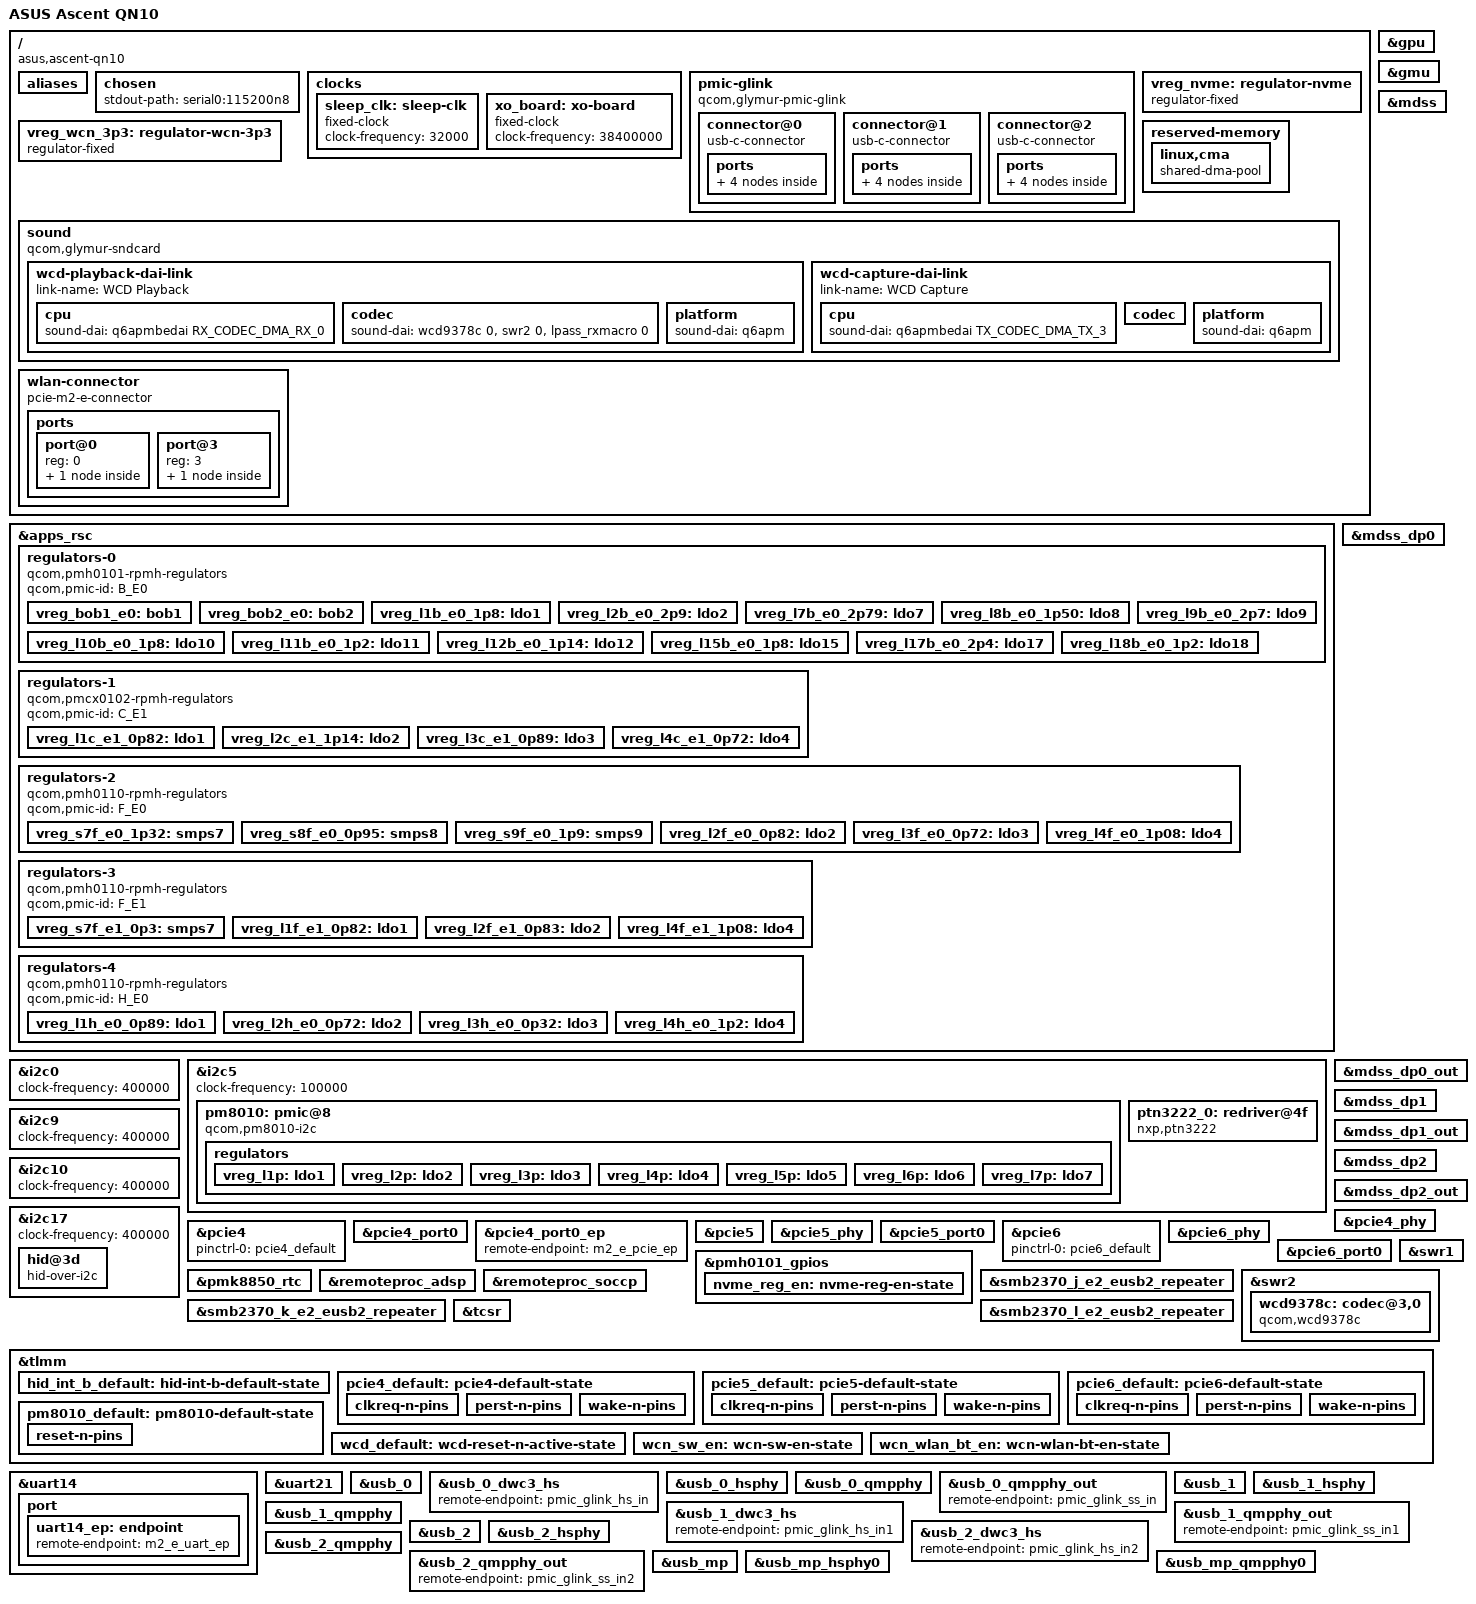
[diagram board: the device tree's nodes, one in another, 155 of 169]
// SPDX-License-Identifier: BSD-3-Clause
/*
 * Copyright (c) Qualcomm Technologies, Inc. and/or its subsidiaries.
 */
/dts-v1/;

#include "glymur.dtsi"

#include "pmcx0102.dtsi"        /* SPMI0: SID-2/3 SPMI1: SID-2/3 */
#include "pmh0101.dtsi"         /* SPMI0: SID-1                  */
#include "pmh0110-glymur.dtsi"  /* SPMI0: SID-5/7 SPMI1: SID-5   */
#include "pmh0104-glymur.dtsi"  /* SPMI0: SID-8/9 SPMI1: SID-11  */
#include "pmk8850.dtsi"         /* SPMI0: SID-0                  */
#include "smb2370.dtsi"         /* SPMI2: SID-9/10/11            */

/ {
	model = "ASUS Ascent QN10";
	compatible = "asus,ascent-qn10", "qcom,glymur";
	chassis-type = "desktop";

	aliases {
		i2c0 = &i2c0;
		i2c5 = &i2c5;
		i2c9 = &i2c9;
		i2c10 = &i2c10;
		i2c17 = &i2c17;

		serial0 = &uart21;
		serial1 = &uart14;
	};

	chosen {
		stdout-path = "serial0:115200n8";
	};

	clocks {
		sleep_clk: sleep-clk {
			compatible = "fixed-clock";
			clock-frequency = <32000>;
			#clock-cells = <0>;
		};

		xo_board: xo-board {
			compatible = "fixed-clock";
			clock-frequency = <38400000>;
			#clock-cells = <0>;
		};
	};

	/*
	 * Three Type-C ports and no battery. The mapping of the connectors to
	 * the USB controllers is not known. The rear HDMI port is not described.
	 */
	pmic-glink {
		compatible = "qcom,glymur-pmic-glink",
			     "qcom,pmic-glink";
		#address-cells = <1>;
		#size-cells = <0>;

		/* Assumed front left */
		connector@0 {
			compatible = "usb-c-connector";
			reg = <0>;
			power-role = "dual";
			data-role = "dual";

			ports {
				#address-cells = <1>;
				#size-cells = <0>;

				port@0 {
					reg = <0>;

					pmic_glink_hs_in: endpoint {
						remote-endpoint = <&usb_0_dwc3_hs>;
					};
				};

				port@1 {
					reg = <1>;

					pmic_glink_ss_in: endpoint {
						remote-endpoint = <&usb_0_qmpphy_out>;
					};
				};
			};
		};

		/* Assumed front right */
		connector@1 {
			compatible = "usb-c-connector";
			reg = <1>;
			power-role = "dual";
			data-role = "dual";

			ports {
				#address-cells = <1>;
				#size-cells = <0>;

				port@0 {
					reg = <0>;

					pmic_glink_hs_in1: endpoint {
						remote-endpoint = <&usb_1_dwc3_hs>;
					};
				};

				port@1 {
					reg = <1>;

					pmic_glink_ss_in1: endpoint {
						remote-endpoint = <&usb_1_qmpphy_out>;
					};
				};
			};
		};

		/* Assumed rear */
		connector@2 {
			compatible = "usb-c-connector";
			reg = <2>;
			power-role = "dual";
			data-role = "dual";

			ports {
				#address-cells = <1>;
				#size-cells = <0>;

				port@0 {
					reg = <0>;

					pmic_glink_hs_in2: endpoint {
						remote-endpoint = <&usb_2_dwc3_hs>;
					};
				};

				port@1 {
					reg = <1>;

					pmic_glink_ss_in2: endpoint {
						remote-endpoint = <&usb_2_qmpphy_out>;
					};
				};
			};
		};
	};

	vreg_nvme: regulator-nvme {
		compatible = "regulator-fixed";

		regulator-name = "VREG_NVME_3P3";
		regulator-min-microvolt = <3300000>;
		regulator-max-microvolt = <3300000>;

		gpio = <&pmh0101_gpios 14 GPIO_ACTIVE_HIGH>;
		enable-active-high;

		pinctrl-0 = <&nvme_reg_en>;
		pinctrl-names = "default";

		regulator-boot-on;
	};

	vreg_wcn_3p3: regulator-wcn-3p3 {
		compatible = "regulator-fixed";

		regulator-name = "VREG_WCN_3P3";
		regulator-min-microvolt = <3300000>;
		regulator-max-microvolt = <3300000>;

		gpio = <&tlmm 94 GPIO_ACTIVE_HIGH>;
		enable-active-high;

		pinctrl-0 = <&wcn_sw_en>;
		pinctrl-names = "default";

		regulator-boot-on;
	};

	reserved-memory {
		linux,cma {
			compatible = "shared-dma-pool";
			size = <0x0 0x10000000>;
			reusable;
			linux,cma-default;
		};
	};

	/*
	 * Only the WCD9378 links are used. There are no WSA amplifiers or
	 * digital microphones.
	 */
	sound {
		compatible = "qcom,glymur-sndcard";
		model = "GLYMUR-ASUS-Ascent-QN10";

		audio-routing = "IT 41 Playback", "HPHL_OUT",
				"IT 41 Playback", "HPHR_OUT",
				/* Bridge the TX macro input to the WCD capture terminal */
				"TX SWR_INPUT1", "OT 36 Capture";

		/*
		 * swr2 is the bus master and swr1 its lane provider, so both DAI
		 * links reference &swr2 (cell 0 dout, cell 1 din).
		 */
		wcd-playback-dai-link {
			link-name = "WCD Playback";

			cpu {
				sound-dai = <&q6apmbedai RX_CODEC_DMA_RX_0>;
			};

			codec {
				sound-dai = <&wcd9378c 0>, <&swr2 0>, <&lpass_rxmacro 0>;
			};

			platform {
				sound-dai = <&q6apm>;
			};
		};

		wcd-capture-dai-link {
			link-name = "WCD Capture";

			cpu {
				sound-dai = <&q6apmbedai TX_CODEC_DMA_TX_3>;
			};

			codec {
				sound-dai = <&wcd9378c 18>, <&swr2 1>, <&lpass_txmacro 0>;
			};

			platform {
				sound-dai = <&q6apm>;
			};
		};
	};

	/*
	 * Generic M.2 E-key connector. The module is a Foxconn NCM820A
	 * (FastConnect C7700, PCI 17cb:1112), not the WCN7850 of the QCB and
	 * CRD. Bluetooth is a UART device on uart14.
	 */
	wlan-connector {
		compatible = "pcie-m2-e-connector";
		vpcie3v3-supply = <&vreg_wcn_3p3>;
		vpcie1v8-supply = <&vreg_l15b_e0_1p8>;

		w-disable1-gpios = <&tlmm 117 GPIO_ACTIVE_LOW>;
		w-disable2-gpios = <&tlmm 116 GPIO_ACTIVE_LOW>;

		pinctrl-0 = <&wcn_wlan_bt_en>;
		pinctrl-names = "default";

		ports {
			#address-cells = <1>;
			#size-cells = <0>;

			port@0 {
				reg = <0>;

				m2_e_pcie_ep: endpoint {
					remote-endpoint = <&pcie4_port0_ep>;
				};
			};

			port@3 {
				reg = <3>;

				m2_e_uart_ep: endpoint {
					remote-endpoint = <&uart14_ep>;
				};
			};
		};
	};
};

/*
 * RPMh regulator table of the CRD family (B_E0, C_E1, F_E0, F_E1, H_E0). The
 * rail plan is assumed to match the CRD.
 */
&apps_rsc {
	regulators-0 {
		compatible = "qcom,pmh0101-rpmh-regulators";
		qcom,pmic-id = "B_E0";

		vreg_bob1_e0: bob1 {
			regulator-name = "vreg_bob1_e0";
			regulator-min-microvolt = <2200000>;
			regulator-max-microvolt = <4224000>;
			regulator-initial-mode = <RPMH_REGULATOR_MODE_AUTO>;
		};

		vreg_bob2_e0: bob2 {
			regulator-name = "vreg_bob2_e0";
			regulator-min-microvolt = <2540000>;
			regulator-max-microvolt = <3600000>;
			regulator-initial-mode = <RPMH_REGULATOR_MODE_AUTO>;
		};

		vreg_l1b_e0_1p8: ldo1 {
			regulator-name = "vreg_l1b_e0_1p8";
			regulator-min-microvolt = <1800000>;
			regulator-max-microvolt = <1800000>;
			regulator-initial-mode = <RPMH_REGULATOR_MODE_HPM>;
		};

		vreg_l2b_e0_2p9: ldo2 {
			regulator-name = "vreg_l2b_e0_2p9";
			regulator-min-microvolt = <2904000>;
			regulator-max-microvolt = <2904000>;
			regulator-initial-mode = <RPMH_REGULATOR_MODE_HPM>;
		};

		vreg_l7b_e0_2p79: ldo7 {
			regulator-name = "vreg_l7b_e0_2p79";
			regulator-min-microvolt = <2790000>;
			regulator-max-microvolt = <2792000>;
			regulator-initial-mode = <RPMH_REGULATOR_MODE_HPM>;
		};

		vreg_l8b_e0_1p50: ldo8 {
			regulator-name = "vreg_l8b_e0_1p50";
			regulator-min-microvolt = <1504000>;
			regulator-max-microvolt = <1504000>;
			regulator-initial-mode = <RPMH_REGULATOR_MODE_HPM>;
		};

		vreg_l9b_e0_2p7: ldo9 {
			regulator-name = "vreg_l9b_e0_2p7";
			regulator-min-microvolt = <2704000>;
			regulator-max-microvolt = <2704000>;
			regulator-initial-mode = <RPMH_REGULATOR_MODE_HPM>;
		};

		vreg_l10b_e0_1p8: ldo10 {
			regulator-name = "vreg_l10b_e0_1p8";
			regulator-min-microvolt = <1800000>;
			regulator-max-microvolt = <1800000>;
			regulator-initial-mode = <RPMH_REGULATOR_MODE_HPM>;
		};

		vreg_l11b_e0_1p2: ldo11 {
			regulator-name = "vreg_l11b_e0_1p2";
			regulator-min-microvolt = <1200000>;
			regulator-max-microvolt = <1200000>;
			regulator-initial-mode = <RPMH_REGULATOR_MODE_HPM>;
		};

		vreg_l12b_e0_1p14: ldo12 {
			regulator-name = "vreg_l12b_e0_1p14";
			regulator-min-microvolt = <1144000>;
			regulator-max-microvolt = <1144000>;
			regulator-initial-mode = <RPMH_REGULATOR_MODE_HPM>;
		};

		vreg_l15b_e0_1p8: ldo15 {
			regulator-name = "vreg_l15b_e0_1p8";
			regulator-min-microvolt = <1800000>;
			regulator-max-microvolt = <1800000>;
			regulator-initial-mode = <RPMH_REGULATOR_MODE_HPM>;
			/* Reference voltage for many undescribed components */
			regulator-always-on;
		};

		vreg_l17b_e0_2p4: ldo17 {
			regulator-name = "vreg_l17b_e0_2p4";
			regulator-min-microvolt = <2400000>;
			regulator-max-microvolt = <2700000>;
			regulator-initial-mode = <RPMH_REGULATOR_MODE_HPM>;
		};

		vreg_l18b_e0_1p2: ldo18 {
			regulator-name = "vreg_l18b_e0_1p2";
			regulator-min-microvolt = <1200000>;
			regulator-max-microvolt = <1200000>;
			regulator-initial-mode = <RPMH_REGULATOR_MODE_HPM>;
			/* Reference voltage for many undescribed components */
			regulator-always-on;
		};
	};

	regulators-1 {
		compatible = "qcom,pmcx0102-rpmh-regulators";
		qcom,pmic-id = "C_E1";

		vreg_l1c_e1_0p82: ldo1 {
			regulator-name = "vreg_l1c_e1_0p82";
			regulator-min-microvolt = <832000>;
			regulator-max-microvolt = <832000>;
			regulator-initial-mode = <RPMH_REGULATOR_MODE_HPM>;
		};

		vreg_l2c_e1_1p14: ldo2 {
			regulator-name = "vreg_l2c_e1_1p14";
			regulator-min-microvolt = <1144000>;
			regulator-max-microvolt = <1144000>;
			regulator-initial-mode = <RPMH_REGULATOR_MODE_HPM>;
		};

		vreg_l3c_e1_0p89: ldo3 {
			regulator-name = "vreg_l3c_e1_0p89";
			regulator-min-microvolt = <890000>;
			regulator-max-microvolt = <980000>;
			regulator-initial-mode = <RPMH_REGULATOR_MODE_HPM>;
		};

		vreg_l4c_e1_0p72: ldo4 {
			regulator-name = "vreg_l4c_e1_0p72";
			regulator-min-microvolt = <720000>;
			regulator-max-microvolt = <720000>;
			regulator-initial-mode = <RPMH_REGULATOR_MODE_HPM>;
		};
	};

	regulators-2 {
		compatible = "qcom,pmh0110-rpmh-regulators";
		qcom,pmic-id = "F_E0";

		vreg_s7f_e0_1p32: smps7 {
			regulator-name = "vreg_s7f_e0_1p32";
			regulator-min-microvolt = <1320000>;
			regulator-max-microvolt = <1352000>;
			regulator-initial-mode = <RPMH_REGULATOR_MODE_HPM>;
		};

		vreg_s8f_e0_0p95: smps8 {
			regulator-name = "vreg_s8f_e0_0p95";
			regulator-min-microvolt = <952000>;
			regulator-max-microvolt = <1200000>;
			regulator-initial-mode = <RPMH_REGULATOR_MODE_HPM>;
		};

		vreg_s9f_e0_1p9: smps9 {
			regulator-name = "vreg_s9f_e0_1p9";
			regulator-min-microvolt = <1900000>;
			regulator-max-microvolt = <2000000>;
			regulator-initial-mode = <RPMH_REGULATOR_MODE_HPM>;
		};

		vreg_l2f_e0_0p82: ldo2 {
			regulator-name = "vreg_l2f_e0_0p82";
			regulator-min-microvolt = <832000>;
			regulator-max-microvolt = <832000>;
			regulator-initial-mode = <RPMH_REGULATOR_MODE_HPM>;
		};

		vreg_l3f_e0_0p72: ldo3 {
			regulator-name = "vreg_l3f_e0_0p72";
			regulator-min-microvolt = <720000>;
			regulator-max-microvolt = <720000>;
			regulator-initial-mode = <RPMH_REGULATOR_MODE_HPM>;
		};

		vreg_l4f_e0_1p08: ldo4 {
			regulator-name = "vreg_l4f_e0_1p08";
			regulator-min-microvolt = <1080000>;
			regulator-max-microvolt = <1200000>;
			regulator-initial-mode = <RPMH_REGULATOR_MODE_HPM>;
		};
	};

	regulators-3 {
		compatible = "qcom,pmh0110-rpmh-regulators";
		qcom,pmic-id = "F_E1";

		vreg_s7f_e1_0p3: smps7 {
			regulator-name = "vreg_s7f_e1_0p3";
			regulator-min-microvolt = <300000>;
			regulator-max-microvolt = <1200000>;
			regulator-initial-mode = <RPMH_REGULATOR_MODE_HPM>;
		};

		vreg_l1f_e1_0p82: ldo1 {
			regulator-name = "vreg_l1f_e1_0p82";
			regulator-min-microvolt = <832000>;
			regulator-max-microvolt = <832000>;
			regulator-initial-mode = <RPMH_REGULATOR_MODE_HPM>;
		};

		vreg_l2f_e1_0p83: ldo2 {
			regulator-name = "vreg_l2f_e1_0p83";
			regulator-min-microvolt = <832000>;
			regulator-max-microvolt = <832000>;
			regulator-initial-mode = <RPMH_REGULATOR_MODE_HPM>;
		};

		vreg_l4f_e1_1p08: ldo4 {
			regulator-name = "vreg_l4f_e1_1p08";
			regulator-min-microvolt = <1080000>;
			regulator-max-microvolt = <1320000>;
			regulator-initial-mode = <RPMH_REGULATOR_MODE_HPM>;
		};
	};

	regulators-4 {
		compatible = "qcom,pmh0110-rpmh-regulators";
		qcom,pmic-id = "H_E0";

		vreg_l1h_e0_0p89: ldo1 {
			regulator-name = "vreg_l1h_e0_0p89";
			regulator-min-microvolt = <832000>;
			regulator-max-microvolt = <832000>;
			regulator-initial-mode = <RPMH_REGULATOR_MODE_HPM>;
		};

		vreg_l2h_e0_0p72: ldo2 {
			regulator-name = "vreg_l2h_e0_0p72";
			regulator-min-microvolt = <832000>;
			regulator-max-microvolt = <832000>;
			regulator-initial-mode = <RPMH_REGULATOR_MODE_HPM>;
		};

		vreg_l3h_e0_0p32: ldo3 {
			regulator-name = "vreg_l3h_e0_0p32";
			regulator-min-microvolt = <320000>;
			regulator-max-microvolt = <2000000>;
			regulator-initial-mode = <RPMH_REGULATOR_MODE_HPM>;
		};

		vreg_l4h_e0_1p2: ldo4 {
			regulator-name = "vreg_l4h_e0_1p2";
			regulator-min-microvolt = <1080000>;
			regulator-max-microvolt = <1320000>;
			regulator-initial-mode = <RPMH_REGULATOR_MODE_HPM>;
		};
	};
};

&gpu {
	status = "okay";
};

&gmu {
	status = "okay";
};

/*
 * The bus carries an ASUS I2C HID device at address 0x3a. Its interrupt is not
 * a TLMM pin, so no child node is given.
 */
&i2c0 {
	clock-frequency = <400000>;

	status = "okay";
};

/*
 * PM8010 PMIC at address 0x08, as on the CRD. ACPI runs this bus at 100 kHz.
 * The eUSB2 repeater of the usb_mp lane 0 is assumed to use the A16 address
 * (0x4f with reset GPIO 8). A second PTN3222 with reset GPIO 184 serves the
 * unused lane 1 and is not described.
 */
&i2c5 {
	clock-frequency = <100000>;

	status = "okay";

	/* The reset GPIO and what the LDOs feed are taken from the CRD */
	pm8010: pmic@8 {
		compatible = "qcom,pm8010-i2c";
		reg = <0x8>;

		reset-gpios = <&tlmm 106 GPIO_ACTIVE_LOW>;

		vdd-l1-l2-supply = <&vreg_l6p>;
		vdd-l3-l4-supply = <&vreg_bob1_e0>;
		vdd-l5-supply = <&vreg_bob1_e0>;
		vdd-l6-supply = <&vreg_bob1_e0>;
		vdd-l7-supply = <&vreg_bob1_e0>;

		pinctrl-0 = <&pm8010_default>;
		pinctrl-names = "default";

		gpio-controller;
		#gpio-cells = <2>;
		gpio-ranges = <&pm8010 0 0 2>;

		#thermal-sensor-cells = <0>;

		regulators {
			vreg_l1p: ldo1 {
				regulator-name = "vreg_l1p";
				regulator-min-microvolt = <1200000>;
				regulator-max-microvolt = <1200000>;
			};

			vreg_l2p: ldo2 {
				regulator-name = "vreg_l2p";
				regulator-min-microvolt = <1200000>;
				regulator-max-microvolt = <1200000>;
			};

			vreg_l3p: ldo3 {
				regulator-name = "vreg_l3p";
				regulator-min-microvolt = <2800000>;
				regulator-max-microvolt = <2800000>;
			};

			vreg_l4p: ldo4 {
				regulator-name = "vreg_l4p";
				regulator-min-microvolt = <1800000>;
				regulator-max-microvolt = <1800000>;
			};

			vreg_l5p: ldo5 {
				regulator-name = "vreg_l5p";
				regulator-min-microvolt = <2800000>;
				regulator-max-microvolt = <2800000>;
			};

			vreg_l6p: ldo6 {
				regulator-name = "vreg_l6p";
				regulator-min-microvolt = <1800000>;
				regulator-max-microvolt = <1800000>;
			};

			vreg_l7p: ldo7 {
				regulator-name = "vreg_l7p";
				regulator-min-microvolt = <2800000>;
				regulator-max-microvolt = <2800000>;
			};
		};
	};

	ptn3222_0: redriver@4f {
		compatible = "nxp,ptn3222";
		reg = <0x4f>;

		reset-gpios = <&tlmm 8 GPIO_ACTIVE_LOW>;

		vdd3v3-supply = <&vreg_l8b_e0_1p50>;
		vdd1v8-supply = <&vreg_l15b_e0_1p8>;

		#phy-cells = <0>;
	};
};

/*
 * The embedded controller at address 0x76 also controls the fans. Its
 * protocol and its interrupt pin are not known, so it is not described.
 */
&i2c9 {
	clock-frequency = <400000>;

	status = "okay";

	/* EC @ 0x76 */
};

/*
 * The bus carries an external RTC at address 0x68 (a Pericom PT7C part;
 * the exact model is not known), which ACPI uses as its time and alarm
 * device. No child node is given.
 */
&i2c10 {
	clock-frequency = <400000>;

	status = "okay";
};

/*
 * I2C HID device at address 0x3d with its interrupt on TLMM 71. Its function
 * is not known. ACPI describes the interrupt as edge, active low, wake
 * capable, with a pull-up.
 */
&i2c17 {
	clock-frequency = <400000>;

	status = "okay";

	hid@3d {
		compatible = "hid-over-i2c";
		reg = <0x3d>;

		hid-descr-addr = <0x1>;
		interrupts-extended = <&tlmm 71 IRQ_TYPE_LEVEL_LOW>;

		pinctrl-0 = <&hid_int_b_default>;
		pinctrl-names = "default";

		wakeup-source;
	};
};

&mdss {
	status = "okay";
};

/* USB-C DP alt mode on the three Type-C ports */
&mdss_dp0 {
	status = "okay";
};

&mdss_dp0_out {
	link-frequencies = /bits/ 64 <1620000000 2700000000 5400000000 8100000000>;
};

&mdss_dp1 {
	status = "okay";
};

&mdss_dp1_out {
	link-frequencies = /bits/ 64 <1620000000 2700000000 5400000000 8100000000>;
};

&mdss_dp2 {
	status = "okay";
};

&mdss_dp2_out {
	link-frequencies = /bits/ 64 <1620000000 2700000000 5400000000 8100000000>;
};

/*
 * Wi-Fi and Bluetooth module on pcie4 (Gen4 x2). WLAN enable is GPIO 117 and
 * Bluetooth enable is GPIO 116. The empty Gen5 M.2 slot, which the firmware
 * leaves off, is not described.
 */
&pcie4 {
	pinctrl-0 = <&pcie4_default>;
	pinctrl-names = "default";

	status = "okay";
};

&pcie4_phy {
	vdda-phy-supply = <&vreg_l1c_e1_0p82>;
	vdda-pll-supply = <&vreg_l4f_e1_1p08>;

	status = "okay";
};

&pcie4_port0 {
	reset-gpios = <&tlmm 146 GPIO_ACTIVE_LOW>;
	wake-gpios = <&tlmm 148 GPIO_ACTIVE_LOW>;
};

/* Link the root port to the M.2 E-key connector */
&pcie4_port0_ep {
	remote-endpoint = <&m2_e_pcie_ep>;
};

/* Primary NVMe slot on pcie5 (Gen4 x4) */
&pcie5 {
	vddpe-3v3-supply = <&vreg_nvme>;

	pinctrl-0 = <&pcie5_default>;
	pinctrl-names = "default";

	status = "okay";
};

&pcie5_phy {
	vdda-phy-supply = <&vreg_l2f_e0_0p82>;
	vdda-pll-supply = <&vreg_l4h_e0_1p2>;

	status = "okay";
};

&pcie5_port0 {
	reset-gpios = <&tlmm 152 GPIO_ACTIVE_LOW>;
	wake-gpios = <&tlmm 154 GPIO_ACTIVE_LOW>;
};

/*
 * Realtek RTL8125 2.5 GbE controller (PCI 10ec:8125) on pcie6 (Gen4 x2). No
 * vddpe supply is given: the controller is soldered and assumed to use an
 * always-on rail.
 */
&pcie6 {
	pinctrl-0 = <&pcie6_default>;
	pinctrl-names = "default";

	status = "okay";
};

&pcie6_phy {
	vdda-phy-supply = <&vreg_l1c_e1_0p82>;
	vdda-pll-supply = <&vreg_l4f_e1_1p08>;

	status = "okay";
};

&pcie6_port0 {
	reset-gpios = <&tlmm 149 GPIO_ACTIVE_LOW>;
	wake-gpios = <&tlmm 151 GPIO_ACTIVE_LOW>;
};

&pmh0101_gpios {
	nvme_reg_en: nvme-reg-en-state {
		pins = "gpio14";
		function = "normal";
		bias-disable;
	};
};

&pmk8850_rtc {
	qcom,no-alarm;
	qcom,uefi-rtc-info;
};

/*
 * Firmware path convention qcom/<soc>/<vendor>/<product>/, as on the A16. The
 * CDSP firmware file names are not known, so the CDSP stays disabled. Without
 * the ADSP firmware, pmic-glink (USB-C role and alt mode) and audio do not
 * work.
 */
&remoteproc_adsp {
	firmware-name = "qcom/glymur/ASUSTeK/QN10/qcadsp8480.mbn",
			"qcom/glymur/ASUSTeK/QN10/adsp_dtbs.elf";

	status = "okay";
};

&remoteproc_soccp {
	firmware-name = "qcom/glymur/ASUSTeK/QN10/soccp.mbn",
			"qcom/glymur/ASUSTeK/QN10/soccp_dtb.mbn";
};

/* The repeater supplies are assumed to follow the A16 pair */
&smb2370_j_e2_eusb2_repeater {
	vdd18-supply = <&vreg_l15b_e0_1p8>;
	vdd3-supply = <&vreg_l7b_e0_2p79>;
};

&smb2370_k_e2_eusb2_repeater {
	vdd18-supply = <&vreg_l15b_e0_1p8>;
	vdd3-supply = <&vreg_l7b_e0_2p79>;
};

&smb2370_l_e2_eusb2_repeater {
	vdd18-supply = <&vreg_l15b_e0_1p8>;
	vdd3-supply = <&vreg_l7b_e0_2p79>;
};

/* Data-only lane provider for the WCD9378 compute-mode bus */
&swr1 {
	#qcom,swrm-lane-cells = <1>;

	status = "okay";
};

/*
 * SoundWire bus master with the WCD9378C codec. The supply rails are assumed
 * from the CRD.
 */
&swr2 {
	qcom,secondary-lanes = <&swr1 0>, <&swr1 1>;

	qcom,ports-block-pack-mode =
		/bits/ 8 <0xff 0xff 0xff 0xff 0xff 0xff 0x00
			  0x01 0xff 0xff 0xff 0xff 0xff 0xff>;
	qcom,ports-word-length =
		/bits/ 8 <0xff 0x01 0xff 0xff 0xff 0x01 0x07
			  0x04 0xff 0xff 0xff 0xff 0xff 0xff>;
	qcom,ports-offset1 =
		/bits/ 8 <0x00 0x01 0x02 0x00 0x00 0x00 0x00
			  0x0b 0x00 0x00 0x00 0x00 0x00 0x00>;
	qcom,ports-offset2 =
		/bits/ 8 <0x00 0x00 0x00 0x00 0xff 0x00 0x00
			  0x0b 0x00 0x00 0x00 0x00 0x00 0x00>;
	qcom,ports-sinterval-low =
		/bits/ 8 <0x00 0x01 0x03 0x03 0x00 0x03 0x1f
			  0x1f 0x00 0x00 0x00 0x00 0x00 0x00>;
	qcom,ports-hstart =
		/bits/ 8 <0xff 0xff 0xff 0xff 0xff 0x00 0x00
			  0x00 0xff 0xff 0xff 0xff 0xff 0xff>;
	qcom,ports-hstop =
		/bits/ 8 <0xff 0x0f 0xff 0xff 0xff 0x0f 0x0f
			  0x0f 0xff 0xff 0xff 0xff 0xff 0xff>;
	qcom,ports-lane-control =
		/bits/ 8 <0xff 0x01 0x00 0x01 0xff 0x03 0x02
			  0x02 0xff 0xff 0xff 0xff 0xff 0xff>;
	qcom,ports-ch-mask =
		/bits/ 8 <0xff 0x01 0xff 0xff 0xff 0x03 0x01
			  0x03 0xff 0xff 0xff 0xff 0xff 0xff>;
	qcom,ports-block-group-count =
		/bits/ 8 <0xff 0xff 0xff 0xff 0xff 0xff 0xff
			  0xff 0xff 0xff 0xff 0xff 0xff 0xff>;

	status = "okay";

	wcd9378c: codec@3,0 {
		compatible = "qcom,wcd9378c", "sdw20217011000";
		reg = <0 3>;

		pinctrl-0 = <&wcd_default>;
		pinctrl-names = "default";

		qcom,port-mapping = <2 2 3 4 5 6 7 8>;

		reset-gpios = <&tlmm 191 GPIO_ACTIVE_LOW>;

		vdd-buck-supply = <&vreg_l15b_e0_1p8>;
		vdd-rxtx-supply = <&vreg_l15b_e0_1p8>;
		vdd-io-supply = <&vreg_l18b_e0_1p2>;
		vdd-mic-bias-supply = <&vreg_bob1_e0>;

		#sound-dai-cells = <1>;
	};
};

&tcsr {
	vdda-qrefrpt0-0p9-supply = <&vreg_l2f_e1_0p83>;
	vdda-qrefrpt1-0p9-supply = <&vreg_l2f_e1_0p83>;
	vdda-qrefrpt2-0p9-supply = <&vreg_l2f_e1_0p83>;
	vdda-qrefrpt3-0p9-supply = <&vreg_l2h_e0_0p72>;
	vdda-qrefrpt4-0p9-supply = <&vreg_l2h_e0_0p72>;
	vdda-qrefrx0-0p9-supply = <&vreg_l2f_e1_0p83>;
	vdda-qrefrx1-0p9-supply = <&vreg_l2f_e1_0p83>;
	vdda-qrefrx2-0p9-supply = <&vreg_l2f_e1_0p83>;
	vdda-qrefrx4-0p9-supply = <&vreg_l2h_e0_0p72>;
	vdda-qrefrx5-0p9-supply = <&vreg_l3f_e0_0p72>;
	vdda-qreftx0-0p9-supply = <&vreg_l3f_e0_0p72>;
	vdda-qreftx0-1p2-supply = <&vreg_l4h_e0_1p2>;
	vdda-qreftx1-0p9-supply = <&vreg_l1f_e1_0p82>;
	vdda-refgen3-0p9-supply = <&vreg_l2f_e0_0p82>;
	vdda-refgen3-1p2-supply = <&vreg_l4h_e0_1p2>;
	vdda-refgen4-0p9-supply = <&vreg_l1f_e1_0p82>;
	vdda-refgen4-1p2-supply = <&vreg_l4f_e1_1p08>;
};

&tlmm {
	gpio-reserved-ranges = <4 4>, /* EC Secure I3C */
			       <10 2>, /* OOB UART */
			       <44 4>, /* TPM */
			       <65 1>, /* EC reset */
			       <90 1>; /* TPM */

	hid_int_b_default: hid-int-b-default-state {
		pins = "gpio71";
		function = "gpio";
		bias-pull-up;
	};

	pcie4_default: pcie4-default-state {
		clkreq-n-pins {
			pins = "gpio147";
			function = "pcie4_clk_req_n";
			drive-strength = <2>;
			bias-pull-up;
		};

		perst-n-pins {
			pins = "gpio146";
			function = "gpio";
			drive-strength = <2>;
			bias-disable;
		};

		wake-n-pins {
			pins = "gpio148";
			function = "gpio";
			drive-strength = <2>;
			bias-pull-up;
		};
	};

	pcie5_default: pcie5-default-state {
		clkreq-n-pins {
			pins = "gpio153";
			function = "pcie5_clk_req_n";
			drive-strength = <2>;
			bias-pull-up;
		};

		perst-n-pins {
			pins = "gpio152";
			function = "gpio";
			drive-strength = <2>;
			bias-disable;
		};

		wake-n-pins {
			pins = "gpio154";
			function = "gpio";
			drive-strength = <2>;
			bias-pull-up;
		};
	};

	pcie6_default: pcie6-default-state {
		clkreq-n-pins {
			pins = "gpio150";
			function = "pcie6_clk_req_n";
			drive-strength = <2>;
			bias-pull-up;
		};

		perst-n-pins {
			pins = "gpio149";
			function = "gpio";
			drive-strength = <2>;
			bias-disable;
		};

		wake-n-pins {
			pins = "gpio151";
			function = "gpio";
			drive-strength = <2>;
			bias-pull-up;
		};
	};

	pm8010_default: pm8010-default-state {
		reset-n-pins {
			pins = "gpio106";
			function = "gpio";
			drive-strength = <2>;
			bias-disable;
		};
	};

	wcd_default: wcd-reset-n-active-state {
		pins = "gpio191";
		function = "gpio";
		drive-strength = <16>;
		bias-disable;
		output-low;
	};

	wcn_sw_en: wcn-sw-en-state {
		pins = "gpio94";
		function = "gpio";
		drive-strength = <2>;
		bias-disable;
	};

	wcn_wlan_bt_en: wcn-wlan-bt-en-state {
		pins = "gpio116", "gpio117";
		function = "gpio";
		drive-strength = <2>;
		bias-disable;
	};
};

&uart14 {
	status = "okay";

	port {
		uart14_ep: endpoint {
			remote-endpoint = <&m2_e_uart_ep>;
		};
	};
};

/* Console UART, as used by the firmware */
&uart21 {
	status = "okay";
};

/* USB-C port 0 */
&usb_0 {
	status = "okay";
};

&usb_0_dwc3_hs {
	remote-endpoint = <&pmic_glink_hs_in>;
};

&usb_0_hsphy {
	vdd-supply = <&vreg_l3f_e0_0p72>;
	vdda12-supply = <&vreg_l4h_e0_1p2>;

	phys = <&smb2370_j_e2_eusb2_repeater>;

	status = "okay";
};

&usb_0_qmpphy {
	vdda-phy-supply = <&vreg_l3f_e0_0p72>;
	vdda-pll-supply = <&vreg_l4h_e0_1p2>;
	refgen-supply = <&vreg_l2f_e0_0p82>;

	status = "okay";
};

&usb_0_qmpphy_out {
	remote-endpoint = <&pmic_glink_ss_in>;
};

/* USB-C port 1 */
&usb_1 {
	status = "okay";
};

&usb_1_dwc3_hs {
	remote-endpoint = <&pmic_glink_hs_in1>;
};

&usb_1_hsphy {
	vdd-supply = <&vreg_l3f_e0_0p72>;
	vdda12-supply = <&vreg_l4h_e0_1p2>;

	phys = <&smb2370_k_e2_eusb2_repeater>;

	status = "okay";
};

&usb_1_qmpphy {
	vdda-phy-supply = <&vreg_l1h_e0_0p89>;
	vdda-pll-supply = <&vreg_l4h_e0_1p2>;
	refgen-supply = <&vreg_l2f_e0_0p82>;

	status = "okay";
};

&usb_1_qmpphy_out {
	remote-endpoint = <&pmic_glink_ss_in1>;
};

/*
 * USB-C port 2. The CRD does not wire usb_2, and the A16 uses its PHY as a
 * fixed DP output. Here it is assumed to be the third Type-C port.
 */
&usb_2 {
	status = "okay";
};

&usb_2_dwc3_hs {
	remote-endpoint = <&pmic_glink_hs_in2>;
};

&usb_2_hsphy {
	vdd-supply = <&vreg_l4c_e1_0p72>;
	vdda12-supply = <&vreg_l4f_e1_1p08>;

	phys = <&smb2370_l_e2_eusb2_repeater>;

	status = "okay";
};

&usb_2_qmpphy {
	vdda-phy-supply = <&vreg_l4c_e1_0p72>;
	vdda-pll-supply = <&vreg_l4f_e1_1p08>;
	refgen-supply = <&vreg_l4f_e1_1p08>;

	status = "okay";
};

&usb_2_qmpphy_out {
	remote-endpoint = <&pmic_glink_ss_in2>;
};

/*
 * Multiport controller with two eUSB2 and SuperSpeed lanes. All Type-A ports,
 * including the USB 2.0 one, sit behind hubs on lane 0. ACPI marks the lane 1
 * ports as not connectable, so its PHYs stay disabled. The USB 2.0-only
 * controller (usb_hs) is off in the running system and stays disabled.
 */
&usb_mp {
	status = "okay";
};

&usb_mp_hsphy0 {
	vdd-supply = <&vreg_l2h_e0_0p72>;
	vdda12-supply = <&vreg_l4h_e0_1p2>;

	phys = <&ptn3222_0>;

	status = "okay";
};

&usb_mp_qmpphy0 {
	vdda-phy-supply = <&vreg_l2h_e0_0p72>;
	vdda-pll-supply = <&vreg_l4h_e0_1p2>;
	refgen-supply = <&vreg_l4f_e1_1p08>;

	status = "okay";
};
